# HDSC_HC32L150JX register map
Vendor: HDSC Co.Ltd; Series: ARMCM0P; File version: 1.2
CPU: CM0 r0p0, little endian, no MPU, no FPU, 3 interrupt priority bits
Registers are 8-bit, read-write, reset 0x0 unless marked. A register's access mark holds for its fields unless they carry their own. Offsets are from the block's base; [hi:lo] are bit positions; {n}, {i} and the like mark numbered series.

## MSC0_UART — desc MSC_UART
Base 0x40038000; alternate view of MSC0_I2C
Same registers: MSC4_UART 0x40037000 (alternate view of MSC4_I2C), MSC5_UART 0x40037100 (alternate view of MSC5_I2C), MSC6_UART 0x40037200 (alternate view of MSC6_I2C), MSC1_UART 0x40038100 (alternate view of MSC1_I2C), MSC2_UART 0x40038200 (alternate view of MSC2_I2C)
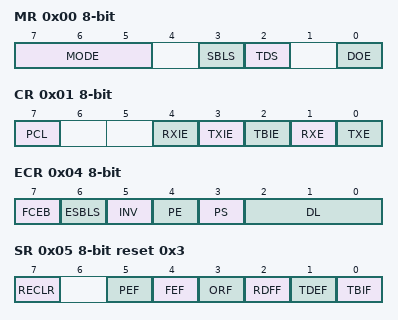
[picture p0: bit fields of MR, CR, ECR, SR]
0x00 MR
  [7:5] MODE, [3] SBLS, [2] TDS, [0] DOE
0x01 CR
  [7] PCL, [4] RXIE, [3] TXIE, [2] TBIE, [1] RXE, [0] TXE
0x04 ECR
  [7] FCEB, [6] ESBLS, [5] INV, [4] PE, [3] PS, [2:0] DL
0x05 SR reset 0x3
  [7] RECLR, [5] PEF ro, [4] FEF ro, [3] ORF ro, [2] RDFF ro, [1] TDEF ro, [0] TBIF ro
0x08 RXDR 16-bit ro (reset mask 0x1FF)
0x08 TXDR 16-bit wo reset 0x1FF (reset mask 0x1FF)
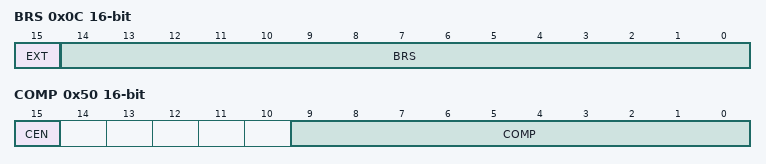
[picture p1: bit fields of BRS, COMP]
0x0C BRS 16-bit
  [15] EXT, [14:0] BRS
0x50 COMP 16-bit
  [15] CEN, [9:0] COMP

## OSC
Base 0x4002E000
0x00 HICR_TRMKEY 32-bit reset 0x1
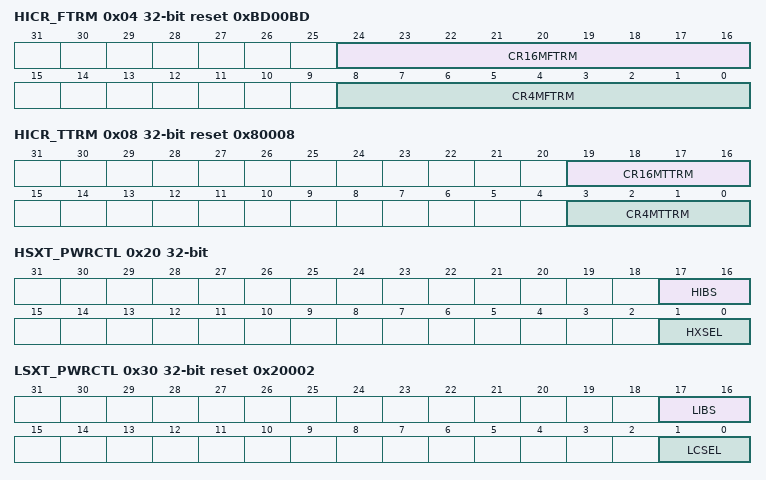
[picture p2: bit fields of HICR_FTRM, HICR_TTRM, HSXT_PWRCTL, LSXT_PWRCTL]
0x04 HICR_FTRM 32-bit reset 0xBD00BD
  [24:16] CR16MFTRM, [8:0] CR4MFTRM
0x08 HICR_TTRM 32-bit reset 0x80008
  [19:16] CR16MTTRM, [3:0] CR4MTTRM
0x0C HICR_FMC reset 0x1
  [1:0] FMC
0x10 HICR_CSR reset 0x1
  [2:0] CSR
0x20 HSXT_PWRCTL 32-bit
  [17:16] HIBS, [1:0] HXSEL
0x30 LSXT_PWRCTL 32-bit reset 0x20002
  [17:16] LIBS, [1:0] LCSEL

## PARITY
Base 0x4003C000
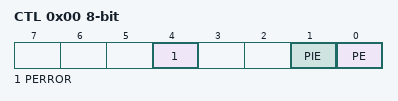
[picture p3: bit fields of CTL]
0x00 CTL
  [4] PERROR, [1] PIE, [0] PE
0x04 ADDR 32-bit

## PCG
Base 0x4003C100
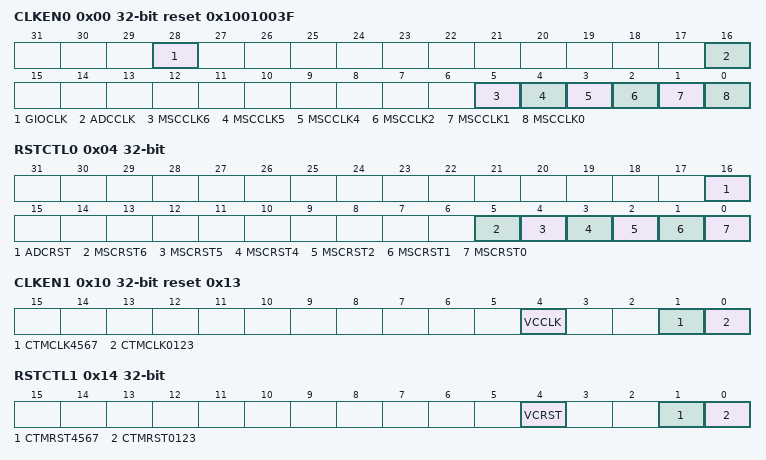
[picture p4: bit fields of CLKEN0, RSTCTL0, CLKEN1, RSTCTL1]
0x00 CLKEN0 32-bit reset 0x1001003F
  [28] GIOCLK, [16] ADCCLK, [5] MSCCLK6, [4] MSCCLK5, [3] MSCCLK4, [2] MSCCLK2, [1] MSCCLK1, [0] MSCCLK0
0x04 RSTCTL0 32-bit
  [16] ADCRST, [5] MSCRST6, [4] MSCRST5, [3] MSCRST4, [2] MSCRST2, [1] MSCRST1, [0] MSCRST0
0x10 CLKEN1 32-bit reset 0x13
  [4] VCCLK, [1] CTMCLK4567, [0] CTMCLK0123
0x14 RSTCTL1 32-bit
  [4] VCRST, [1] CTMRST4567, [0] CTMRST0123
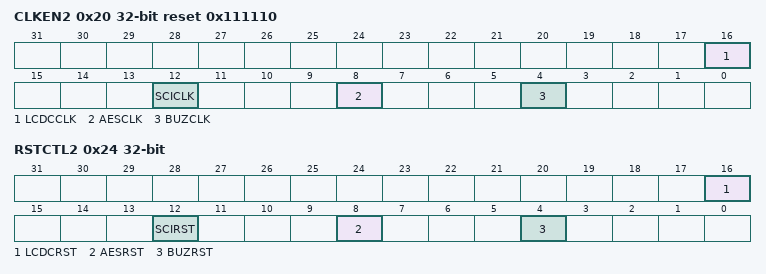
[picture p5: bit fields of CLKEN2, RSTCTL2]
0x20 CLKEN2 32-bit reset 0x111110
  [16] LCDCCLK, [12] SCICLK, [8] AESCLK, [4] BUZCLK
0x24 RSTCTL2 32-bit
  [16] LCDCRST, [12] SCIRST, [8] AESRST, [4] BUZRST

## RTC
Base 0x4003B000
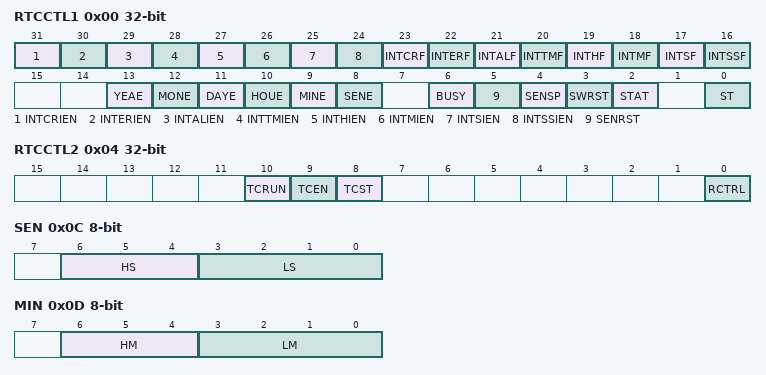
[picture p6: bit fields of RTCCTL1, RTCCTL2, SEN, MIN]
0x00 RTCCTL1 32-bit
  [31] INTCRIEN, [30] INTERIEN, [29] INTALIEN, [28] INTTMIEN, [27] INTHIEN, [26] INTMIEN, [25] INTSIEN, [24] INTSSIEN, [23] INTCRF, [22] INTERF, [21] INTALF, [20] INTTMF, [19] INTHF, [18] INTMF, [17] INTSF, [16] INTSSF, [13] YEAE, [12] MONE, [11] DAYE, [10] HOUE, [9] MINE, [8] SENE, [6] BUSY ro, [5] SENRST, [4] SENSP, [3] SWRST, [2] STAT ro, [0] ST
0x04 RTCCTL2 32-bit
  [10] TCRUN ro, [9] TCEN, [8] TCST, [0] RCTRL
0x08 CCS 32-bit
  [23:0] CC
0x0C SEN
  [6:4] HS, [3:0] LS
0x0D MIN
  [6:4] HM, [3:0] LM
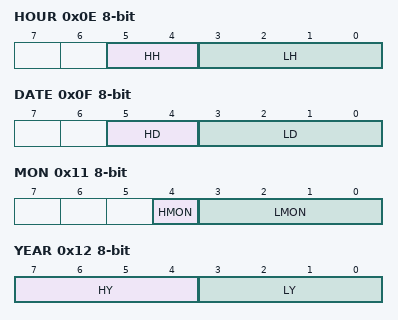
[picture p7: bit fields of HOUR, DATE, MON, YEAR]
0x0E HOUR
  [5:4] HH, [3:0] LH
0x0F DATE
  [5:4] HD, [3:0] LD
0x10 WEEK
  [2:0] WK
0x11 MON
  [4] HMON, [3:0] LMON
0x12 YEAR
  [7:4] HY, [3:0] LY
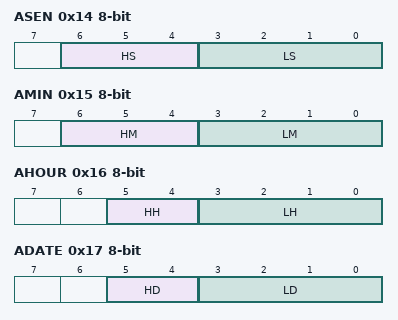
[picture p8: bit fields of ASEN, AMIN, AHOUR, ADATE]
0x14 ASEN
  [6:4] HS, [3:0] LS
0x15 AMIN
  [6:4] HM, [3:0] LM
0x16 AHOUR
  [5:4] HH, [3:0] LH
0x17 ADATE
  [5:4] HD, [3:0] LD
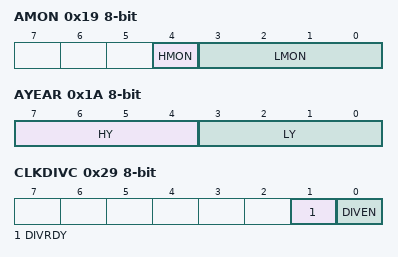
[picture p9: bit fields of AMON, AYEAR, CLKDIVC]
0x19 AMON
  [4] HMON, [3:0] LMON
0x1A AYEAR
  [7:4] HY, [3:0] LY
0x1C TVAL 32-bit
  [17:0] VAL
0x20 SCLKI
  [0] SCLKI
0x21 SCLKS ro
  [1:0] SCLKS
0x24 CALVAL 16-bit
  [9:0] CALVAL
0x26 CALEN
  [0] CALEN
0x28 CLKDIVX
  [3:0] DIVX
0x29 CLKDIVC
  [1] DIVRDY ro, [0] DIVEN
0x2C CALCYC 16-bit reset 0x13
  [8:0] CALCYC
0x30 RTCODIV
  [0] CODIV2

## SBSSR
Base 0x40025F00
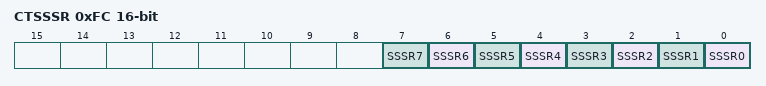
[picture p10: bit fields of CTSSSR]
0xFC CTSSSR 16-bit wo
  [n] SSSR{n} (n=0..7)

## SCI
Base 0x4003C800
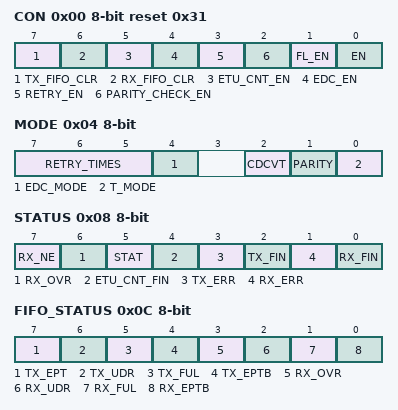
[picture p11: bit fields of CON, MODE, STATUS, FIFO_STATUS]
0x00 CON reset 0x31
  [7] TX_FIFO_CLR, [6] RX_FIFO_CLR, [5] ETU_CNT_EN, [4] EDC_EN, [3] RETRY_EN, [2] PARITY_CHECK_EN, [1] FL_EN, [0] EN
0x04 MODE
  [7:5] RETRY_TIMES, [4] EDC_MODE, [2] CDCVT, [1] PARITY, [0] T_MODE
0x08 STATUS
  [7] RX_NE ro, [6] RX_OVR, [5] STAT ro, [4] ETU_CNT_FIN, [3] TX_ERR, [2] TX_FIN, [1] RX_ERR, [0] RX_FIN
0x0C FIFO_STATUS ro
  [7] TX_EPT, [6] TX_UDR, [5] TX_FUL, [4] TX_EPTB, [3] RX_OVR, [2] RX_UDR, [1] RX_FUL, [0] RX_EPTB
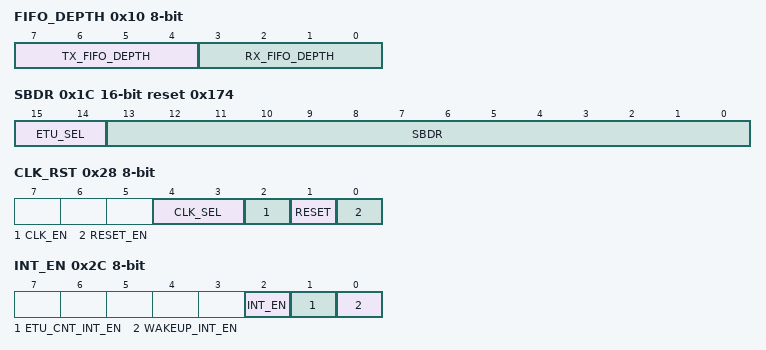
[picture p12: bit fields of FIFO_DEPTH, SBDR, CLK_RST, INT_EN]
0x10 FIFO_DEPTH ro
  [7:4] TX_FIFO_DEPTH, [3:0] RX_FIFO_DEPTH
0x14 DATA
0x18 EDC_DATA 16-bit
0x1C SBDR 16-bit reset 0x174
  [15:14] ETU_SEL, [13:0] SBDR
0x20 ETU_CNT 16-bit reset 0x2580
0x24 F1_NUM
  [2:0] FL_NUM
0x28 CLK_RST
  [4:3] CLK_SEL, [2] CLK_EN, [1] RESET, [0] RESET_EN
0x2C INT_EN
  [2] INT_EN, [1] ETU_CNT_INT_EN, [0] WAKEUP_INT_EN
0x30 WAKEUP_INT
  [0] WAKEUP_INT

## SWWDT
Base 0x40012000
0x00 WDT_LD 32-bit reset 0xFFFFFFFF
0x04 WDT_VL 32-bit ro reset 0xFFFFFFFF
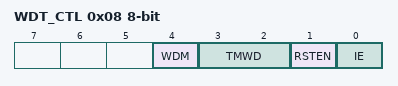
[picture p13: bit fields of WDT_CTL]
0x08 WDT_CTL
  [4] WDM, [3:2] TMWD, [1] RSTEN, [0] IE
0x0C WDT_INTCLR 32-bit
0x10 WDT_STA ro
  [0] STA
0x18 WDT_MDC
  [0] TRG
0xC00 WDT_LCK 32-bit

## UID
Base 0x40000200
0x00 UIDR0 32-bit ro
  [31:0] UID
0x04 UIDR1 32-bit ro
  [31:0] UID
0x08 UIDR2 32-bit ro
  [15:0] UID

## VC
Base 0x4003C300
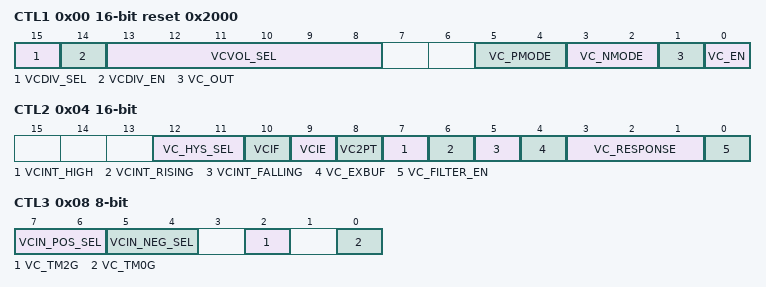
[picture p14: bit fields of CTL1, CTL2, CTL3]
0x00 CTL1 16-bit reset 0x2000
  [15] VCDIV_SEL, [14] VCDIV_EN, [13:8] VCVOL_SEL, [5:4] VC_PMODE, [3:2] VC_NMODE, [1] VC_OUT ro, [0] VC_EN
0x04 CTL2 16-bit
  [12:11] VC_HYS_SEL, [10] VCIF, [9] VCIE, [8] VC2PT, [7] VCINT_HIGH, [6] VCINT_RISING, [5] VCINT_FALLING, [4] VC_EXBUF, [3:1] VC_RESPONSE, [0] VC_FILTER_EN
0x08 CTL3
  [7:6] VCIN_POS_SEL, [5:4] VCIN_NEG_SEL, [2] VC_TM2G, [0] VC_TM0G

## WSUNIT
Base 0x40035000
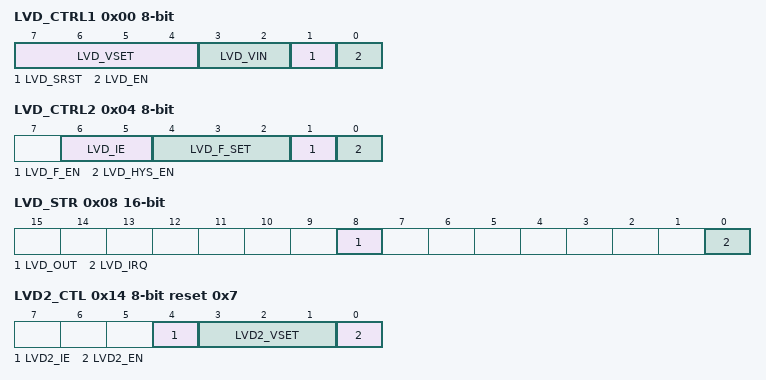
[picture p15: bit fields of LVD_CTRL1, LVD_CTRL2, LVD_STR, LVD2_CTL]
0x00 LVD_CTRL1
  [7:4] LVD_VSET, [3:2] LVD_VIN, [1] LVD_SRST, [0] LVD_EN
0x04 LVD_CTRL2
  [6:5] LVD_IE, [4:2] LVD_F_SET, [1] LVD_F_EN, [0] LVD_HYS_EN
0x08 LVD_STR 16-bit ro
  [8] LVD_OUT, [0] LVD_IRQ
0x0C LVD_CLR reset 0x1
  [0] LVD_CLR
0x14 LVD2_CTL reset 0x7
  [4] LVD2_IE, [3:1] LVD2_VSET, [0] LVD2_EN
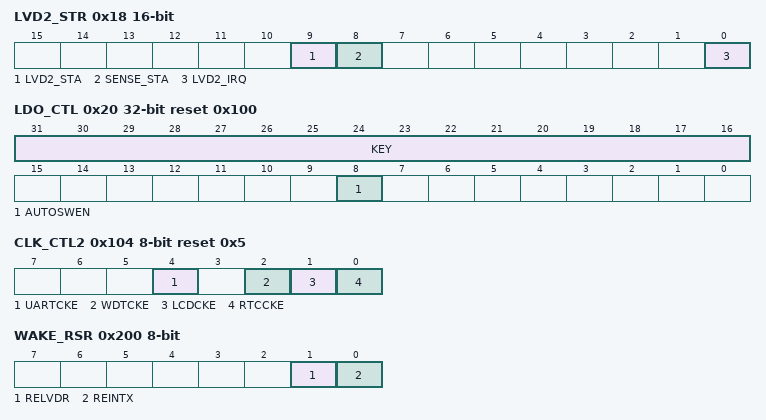
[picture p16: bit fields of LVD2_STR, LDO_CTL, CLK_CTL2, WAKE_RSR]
0x18 LVD2_STR 16-bit ro
  [9] LVD2_STA, [8] SENSE_STA, [0] LVD2_IRQ
0x1C LVD2_CLR reset 0x1
  [0] LVD2_CLR
0x20 LDO_CTL 32-bit reset 0x100
  [31:16] KEY wo, [8] AUTOSWEN
0x30 BGR_CTL
  [0] BGR_EN
0x100 CLK_CTL1
  [0] RTCE
0x104 CLK_CTL2 reset 0x5
  [4] UARTCKE, [2] WDTCKE, [1] LCDCKE, [0] RTCCKE
0x108 MOSC_CTL reset 0x2
  [1:0] IMAINSEL
0x10C DS_RAMP
  [0] RAMP
0x200 WAKE_RSR ro
  [1] RELVDR, [0] REINTX
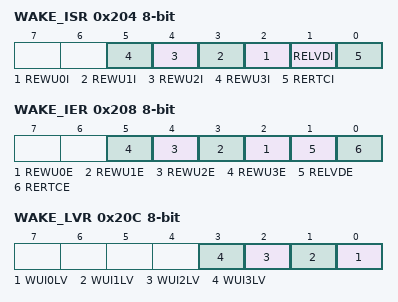
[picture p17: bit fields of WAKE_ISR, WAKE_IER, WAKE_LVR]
0x204 WAKE_ISR ro
  [n+2] REWU{n}I (n=0..3), [1] RELVDI, [0] RERTCI
0x208 WAKE_IER
  [n+2] REWU{n}E (n=0..3), [1] RELVDE, [0] RERTCE
0x20C WAKE_LVR
  [n] WUI{n}LV (n=0..3)
{0x6FF+i} BUR{i:02} (i=1..16)
